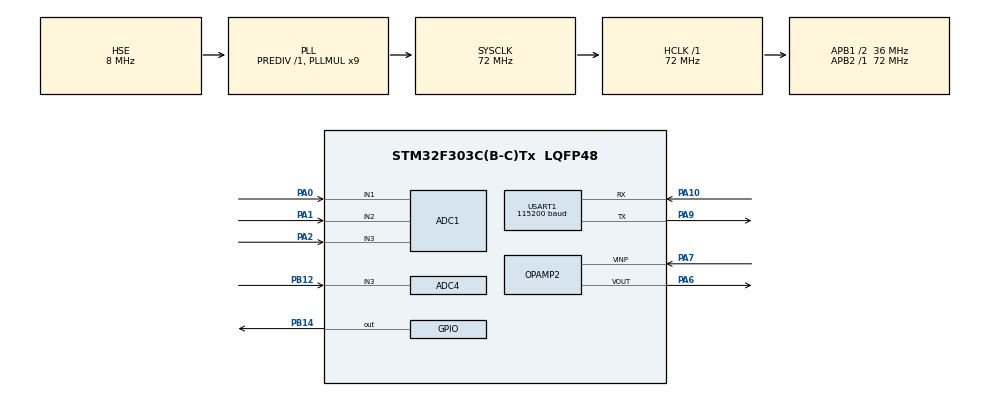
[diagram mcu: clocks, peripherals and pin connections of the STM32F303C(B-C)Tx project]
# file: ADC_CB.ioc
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ADC1.Channel-0\#ChannelRegularConversion=ADC_CHANNEL_1
ADC1.Channel-1\#ChannelRegularConversion=ADC_CHANNEL_2
ADC1.Channel-2\#ChannelRegularConversion=ADC_CHANNEL_3
ADC1.ClockPrescaler=ADC_CLOCK_ASYNC_DIV1
ADC1.EOCSelection=ADC_EOC_SINGLE_CONV
ADC1.EnableInjectedConversion=DISABLE
ADC1.EnableRegularConversion=ENABLE
ADC1.NbrOfConversion=3
ADC1.NbrOfConversionFlag=1
ADC1.Offset-0\#ChannelRegularConversion=0
ADC1.Offset-1\#ChannelRegularConversion=0
ADC1.Offset-2\#ChannelRegularConversion=0
ADC1.OffsetNumber-0\#ChannelRegularConversion=ADC_OFFSET_NONE
ADC1.OffsetNumber-1\#ChannelRegularConversion=ADC_OFFSET_NONE
ADC1.OffsetNumber-2\#ChannelRegularConversion=ADC_OFFSET_NONE
ADC1.Rank-0\#ChannelRegularConversion=1
ADC1.Rank-1\#ChannelRegularConversion=2
ADC1.Rank-2\#ChannelRegularConversion=3
ADC1.SamplingTime-0\#ChannelRegularConversion=ADC_SAMPLETIME_601CYCLES_5
ADC1.SamplingTime-1\#ChannelRegularConversion=ADC_SAMPLETIME_601CYCLES_5
ADC1.SamplingTime-2\#ChannelRegularConversion=ADC_SAMPLETIME_601CYCLES_5
ADC1.master=1
ADC4.Channel-0\#ChannelRegularConversion=ADC_CHANNEL_3
ADC4.EnableInjectedConversion=DISABLE
ADC4.EnableRegularConversion=ENABLE
ADC4.NbrOfConversionFlag=1
ADC4.Offset-0\#ChannelRegularConversion=0
ADC4.OffsetNumber-0\#ChannelRegularConversion=ADC_OFFSET_NONE
ADC4.Rank-0\#ChannelRegularConversion=1
ADC4.SamplingTime-0\#ChannelRegularConversion=ADC_SAMPLETIME_601CYCLES_5
Mcu.Family=STM32F3
Mcu.Name=STM32F303C(B-C)Tx
Mcu.Package=LQFP48
NVIC.ADC1_2_IRQn=true\:0\:0\:false\:false\:true\:true
NVIC.ADC4_IRQn=true\:0\:0\:false\:false\:true\:true
NVIC.PriorityGroup=NVIC_PRIORITYGROUP_4
PA0.Mode=IN1-Single-Ended
PA0.Signal=ADC1_IN1
PA1.Mode=IN2-Single-Ended
PA1.Signal=ADC1_IN2
PA10.Mode=Asynchronous
PA10.Signal=USART1_RX
PA2.Mode=IN3-Single-Ended
PA2.Signal=ADC1_IN3
PA6.Mode=Follower
PA6.Signal=OPAMP2_VOUT
PA7.Mode=Follower
PA7.Signal=OPAMP2_VINP
PA9.Mode=Asynchronous
PA9.Signal=USART1_TX
PB12.Mode=IN3-Single-Ended
PB12.Signal=ADC4_IN3
PB14.PinState=GPIO_PIN_SET
PB14.Signal=GPIO_Output
PF0-OSC_IN.Mode=HSE-External-Oscillator
PF0-OSC_IN.Signal=RCC_OSC_IN
PF1-OSC_OUT.Mode=HSE-External-Oscillator
PF1-OSC_OUT.Signal=RCC_OSC_OUT
ProjectManager.HeapSize=0x200
ProjectManager.StackSize=0x400
ProjectManager.TargetToolchain=Makefile
RCC.AHBFreq_Value=72000000
RCC.APB1CLKDivider=RCC_HCLK_DIV2
RCC.APB1Freq_Value=36000000
RCC.APB1TimFreq_Value=72000000
RCC.APB2Freq_Value=72000000
RCC.APB2TimFreq_Value=72000000
RCC.CortexFreq_Value=72000000
RCC.HCLKFreq_Value=72000000
RCC.HSE_VALUE=8000000
RCC.HSI_VALUE=8000000
RCC.LSE_VALUE=32768
RCC.PLLMUL=RCC_PLL_MUL9
RCC.PLLSourceVirtual=RCC_PLLSOURCE_HSE
RCC.SYSCLKFreq_VALUE=72000000
RCC.SYSCLKSourceVirtual=RCC_SYSCLKSOURCE_PLLCLK
RCC.USBFreq_Value=72000000
USART1.BaudRate=115200
USART1.VirtualMode-Asynchronous=VM_ASYNC
board=ADC_CB

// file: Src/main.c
/**
  ******************************************************************************
  * @file           : main.c
  * @brief          : Main program body
  ******************************************************************************
  ** This notice applies to any and all portions of this file
  * that are not between comment pairs USER CODE BEGIN and
  * USER CODE END. Other portions of this file, whether
  * inserted by the user or by software development tools
  * are owned by their respective copyright owners.
  *
  * COPYRIGHT(c) 2019 STMicroelectronics
  *
  * Redistribution and use in source and binary forms, with or without modification,
  * are permitted provided that the following conditions are met:
  *   1. Redistributions of source code must retain the above copyright notice,
  *      this list of conditions and the following disclaimer.
  *   2. Redistributions in binary form must reproduce the above copyright notice,
  *      this list of conditions and the following disclaimer in the documentation
  *      and/or other materials provided with the distribution.
  *   3. Neither the name of STMicroelectronics nor the names of its contributors
  *      may be used to endorse or promote products derived from this software
  *      without specific prior written permission.
  *
  * THIS SOFTWARE IS PROVIDED BY THE COPYRIGHT HOLDERS AND CONTRIBUTORS "AS IS"
  * AND ANY EXPRESS OR IMPLIED WARRANTIES, INCLUDING, BUT NOT LIMITED TO, THE
  * IMPLIED WARRANTIES OF MERCHANTABILITY AND FITNESS FOR A PARTICULAR PURPOSE ARE
  * DISCLAIMED. IN NO EVENT SHALL THE COPYRIGHT HOLDER OR CONTRIBUTORS BE LIABLE
  * FOR ANY DIRECT, INDIRECT, INCIDENTAL, SPECIAL, EXEMPLARY, OR CONSEQUENTIAL
  * DAMAGES (INCLUDING, BUT NOT LIMITED TO, PROCUREMENT OF SUBSTITUTE GOODS OR
  * SERVICES; LOSS OF USE, DATA, OR PROFITS; OR BUSINESS INTERRUPTION) HOWEVER
  * CAUSED AND ON ANY THEORY OF LIABILITY, WHETHER IN CONTRACT, STRICT LIABILITY,
  * OR TORT (INCLUDING NEGLIGENCE OR OTHERWISE) ARISING IN ANY WAY OUT OF THE USE
  * OF THIS SOFTWARE, EVEN IF ADVISED OF THE POSSIBILITY OF SUCH DAMAGE.
  *
  ******************************************************************************
  */
#include "main.h"
#include "stm32f3xx_hal.h"
#include "adc.h"
#include "opamp.h"
#include "usart.h"
#include "gpio.h"

/* USER CODE BEGIN PV */
/* Private variables ---------------------------------------------------------*/

/* USER CODE END PV */

void SystemClock_Config(void);

/* USER CODE BEGIN PFP */
/* Private function prototypes -----------------------------------------------*/

/* USER CODE END PFP */

int main(void)
{

  /* MCU Configuration----------------------------------------------------------*/

  /* Reset of all peripherals, Initializes the Flash interface and the Systick. */
  HAL_Init();

  /* Configure the system clock */
  SystemClock_Config();

  /* Initialize all configured peripherals */
  MX_GPIO_Init();
  MX_ADC1_Init();
  MX_USART1_UART_Init();
  MX_OPAMP2_Init();
  MX_ADC4_Init();
  /* USER CODE BEGIN 2 */

  HAL_OPAMP_Start(&hopamp2);
  /* USER CODE END 2 */

  /* Infinite loop */
  /* USER CODE BEGIN WHILE */
  while (1)
  {
    HAL_ADC_Start_IT(&hadc1);
    HAL_ADC_Start_IT(&hadc4);
    HAL_GPIO_TogglePin(GPIOB, GPIO_PIN_14);
    HAL_Delay(100);
  /* USER CODE END WHILE */

  }

}

void SystemClock_Config(void)
{

  RCC_OscInitTypeDef RCC_OscInitStruct;
  RCC_ClkInitTypeDef RCC_ClkInitStruct;
  RCC_PeriphCLKInitTypeDef PeriphClkInit;

    /**Initializes the CPU, AHB and APB busses clocks
    */
  RCC_OscInitStruct.OscillatorType = RCC_OSCILLATORTYPE_HSE;
  RCC_OscInitStruct.HSEState = RCC_HSE_ON;
  RCC_OscInitStruct.HSEPredivValue = RCC_HSE_PREDIV_DIV1;
  RCC_OscInitStruct.HSIState = RCC_HSI_ON;
  RCC_OscInitStruct.PLL.PLLState = RCC_PLL_ON;
  RCC_OscInitStruct.PLL.PLLSource = RCC_PLLSOURCE_HSE;
  RCC_OscInitStruct.PLL.PLLMUL = RCC_PLL_MUL9;
  if (HAL_RCC_OscConfig(&RCC_OscInitStruct) != HAL_OK)
  {
    _Error_Handler(__FILE__, __LINE__);
  }

    /**Initializes the CPU, AHB and APB busses clocks
    */
  RCC_ClkInitStruct.ClockType = RCC_CLOCKTYPE_HCLK|RCC_CLOCKTYPE_SYSCLK
                              |RCC_CLOCKTYPE_PCLK1|RCC_CLOCKTYPE_PCLK2;
  RCC_ClkInitStruct.SYSCLKSource = RCC_SYSCLKSOURCE_PLLCLK;
  RCC_ClkInitStruct.AHBCLKDivider = RCC_SYSCLK_DIV1;
  RCC_ClkInitStruct.APB1CLKDivider = RCC_HCLK_DIV2;
  RCC_ClkInitStruct.APB2CLKDivider = RCC_HCLK_DIV1;

  if (HAL_RCC_ClockConfig(&RCC_ClkInitStruct, FLASH_LATENCY_2) != HAL_OK)
  {
    _Error_Handler(__FILE__, __LINE__);
  }

  PeriphClkInit.PeriphClockSelection = RCC_PERIPHCLK_USART1|RCC_PERIPHCLK_ADC12
                              |RCC_PERIPHCLK_ADC34;
  PeriphClkInit.Usart1ClockSelection = RCC_USART1CLKSOURCE_PCLK2;
  PeriphClkInit.Adc12ClockSelection = RCC_ADC12PLLCLK_DIV1;
  PeriphClkInit.Adc34ClockSelection = RCC_ADC34PLLCLK_DIV1;
  if (HAL_RCCEx_PeriphCLKConfig(&PeriphClkInit) != HAL_OK)
  {
    _Error_Handler(__FILE__, __LINE__);
  }

    /**Configure the Systick interrupt time
    */
  HAL_SYSTICK_Config(HAL_RCC_GetHCLKFreq()/1000);

    /**Configure the Systick
    */
  HAL_SYSTICK_CLKSourceConfig(SYSTICK_CLKSOURCE_HCLK);

  /* SysTick_IRQn interrupt configuration */
  HAL_NVIC_SetPriority(SysTick_IRQn, 0, 0);
}

void _Error_Handler(char *file, int line)
{
  while(1)
  {
  }
}

/************************ (C) COPYRIGHT STMicroelectronics *****END OF FILE****/
